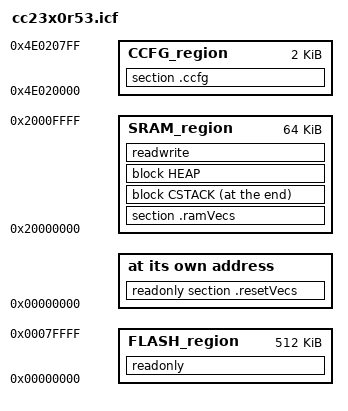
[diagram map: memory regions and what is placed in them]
//*****************************************************************************
//! @file       cc23x0r53.icf
//! @brief      CC23X0R53 linker file for IAR.
//
//  Copyright (c) 2024 Texas Instruments Incorporated
//
//  Redistribution and use in source and binary forms, with or without
//  modification, are permitted provided that the following conditions are met:
//
//  1) Redistributions of source code must retain the above copyright notice,
//     this list of conditions and the following disclaimer.
//
//  2) Redistributions in binary form must reproduce the above copyright notice,
//     this list of conditions and the following disclaimer in the documentation
//     and/or other materials provided with the distribution.
//
//  3) Neither the name of the copyright holder nor the names of its
//     contributors may be used to endorse or promote products derived from this
//     software without specific prior written permission.
//
//  THIS SOFTWARE IS PROVIDED BY THE COPYRIGHT HOLDERS AND CONTRIBUTORS "AS IS"
//  AND ANY EXPRESS OR IMPLIED WARRANTIES, INCLUDING, BUT NOT LIMITED TO, THE
//  IMPLIED WARRANTIES OF MERCHANTABILITY AND FITNESS FOR A PARTICULAR PURPOSE
//  ARE DISCLAIMED. IN NO EVENT SHALL THE COPYRIGHT HOLDER OR CONTRIBUTORS BE
//  LIABLE FOR ANY DIRECT, INDIRECT, INCIDENTAL, SPECIAL, EXEMPLARY, OR
//  CONSEQUENTIAL DAMAGES (INCLUDING, BUT NOT LIMITED TO, PROCUREMENT OF
//  SUBSTITUTE GOODS OR SERVICES; LOSS OF USE, DATA, OR PROFITS; OR BUSINESS
//  INTERRUPTION) HOWEVER CAUSED AND ON ANY THEORY OF LIABILITY, WHETHER IN
//  CONTRACT, STRICT LIABILITY, OR TORT (INCLUDING NEGLIGENCE OR OTHERWISE)
//  ARISING IN ANY WAY OUT OF THE USE OF THIS SOFTWARE, EVEN IF ADVISED OF THE
//  POSSIBILITY OF SUCH DAMAGE.
//
//****************************************************************************/

/* Symbols used for checksum generation */
define exported symbol ti_utils_build_GenMap_sym_CRC_CCFG_BOOT_CFG_begin = 0x4e020000;
define exported symbol ti_utils_build_GenMap_sym_CRC_CCFG_BOOT_CFG_end = 0x4e02000b;
define exported symbol ti_utils_build_GenMap_sym_CRC_CCFG_begin = 0x4e020010;
define exported symbol ti_utils_build_GenMap_sym_CRC_CCFG_end = 0x4e02074b;
define exported symbol ti_utils_build_GenMap_sym_CRC_CCFG_DEBUG_begin = 0x4e0207d0;
define exported symbol ti_utils_build_GenMap_sym_CRC_CCFG_DEBUG_end = 0x4e0207fb;
define exported symbol ti_utils_build_GenMap_sym_CRC_CCFG_USER_RECORD_begin = 0x4e020750;
define exported symbol ti_utils_build_GenMap_sym_CRC_CCFG_USER_RECORD_end = 0x4e0207cb;

/*###ICF### Section handled by ICF editor, don't touch! ****/
/*-Editor annotation file-*/
/* IcfEditorFile="$TOOLKIT_DIR$\config\ide\IcfEditor\cortex_v1_0.xml" */
/*-Specials-*/
define symbol __ICFEDIT_intvec_start__     = 0x00000000;
/*-Memory Regions-*/
define symbol __ICFEDIT_region_ROM_start__ = 0x00000000;
define symbol __ICFEDIT_region_ROM_end__   = 0x0007FFFF;
define symbol __ICFEDIT_region_RAM_start__ = 0x20000000;
define symbol __ICFEDIT_region_RAM_end__   = 0x2000FFFF;
/*-Sizes-*/
define symbol __ICFEDIT_size_cstack__      = 0x800;
define symbol __ICFEDIT_size_heap__        = 0x1000;
/**** End of ICF editor section. ###ICF###*/

define symbol __CCFG_START__               = 0x4E020000;
define symbol __CCFG_END__                 = 0x4E0207FF;

//
// Define a memory region that covers the entire 4 GB addressable space of the
// processor.
//
define memory mem with size = 4G;

//
// Define a region for the on-chip flash.
//
define region FLASH_region   = mem:[from __ICFEDIT_region_ROM_start__ to __ICFEDIT_region_ROM_end__];

//
// Define a region for the on-chip SRAM.
//
define region SRAM_region     = mem:[from __ICFEDIT_region_RAM_start__ to __ICFEDIT_region_RAM_end__];

//
// Place the interrupt vectors at the start of flash.
//
place at address mem:__ICFEDIT_intvec_start__ { readonly section .resetVecs };
keep { section .resetVecs };

//
// Define a region for CCFG
//
define region CCFG_region    = mem:[from __CCFG_START__ to __CCFG_END__];
place in CCFG_region {section .ccfg};
keep { section .ccfg };

//
// Place remaining 'read only' in Flash
//
place in FLASH_region { readonly };


//
// Place .ramVecs in RAM
//
place in SRAM_region { section .ramVecs };
do not initialize { section .ramVecs };

//
// Define CSTACK block to contain .stack section. This enables the IAR IDE
// to properly show the stack content during debug. Place stack at end of
// retention RAM, do not initialize (initializing the stack will destroy the
// return address from the initialization code, causing the processor to branch
// to zero and fault)
//
define block CSTACK with alignment = 8, size = __ICFEDIT_size_cstack__ { section .stack };
place at end of SRAM_region { block CSTACK };
do not initialize { section .stack, section .noinit};

//
// Export stack top symbol. Used by startup file.
//
define exported symbol STACK_TOP = __ICFEDIT_region_RAM_end__ + 1;

//
// Define a block for the heap.  The size should be set to something other
// than zero if things in the C library that require the heap are used.
//
define block HEAP with alignment = 8, size = __ICFEDIT_size_heap__ { };
place in SRAM_region { block HEAP };

//
// Place all read/write items into RAM.
//
place in SRAM_region   { readwrite };
initialize by copy { readwrite };
